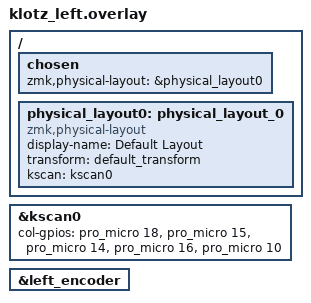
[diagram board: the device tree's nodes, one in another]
/*
 * Copyright (c) 2022 GEIST
 *
 * SPDX-License-Identifier: MIT
 */

#include "klotz.dtsi"

&kscan0 {
	col-gpios
		= <&pro_micro 18 GPIO_ACTIVE_HIGH>
		, <&pro_micro 15 GPIO_ACTIVE_HIGH>
		, <&pro_micro 14 GPIO_ACTIVE_HIGH>
		, <&pro_micro 16 GPIO_ACTIVE_HIGH>
		, <&pro_micro 10 GPIO_ACTIVE_HIGH>
		;
};

&left_encoder {
	status = "okay";
};
/ {
    chosen {
        zmk,physical-layout = &physical_layout0;
    };

    physical_layout0: physical_layout_0 {
        compatible = "zmk,physical-layout";
        display-name = "Default Layout";
        transform = <&default_transform>;
        kscan = <&kscan0>;
    };
};
